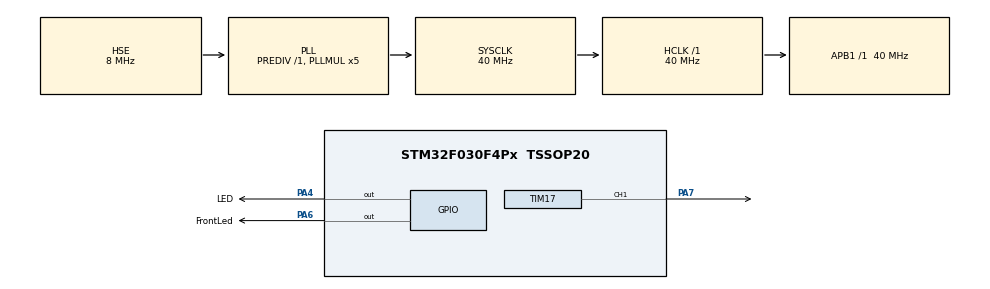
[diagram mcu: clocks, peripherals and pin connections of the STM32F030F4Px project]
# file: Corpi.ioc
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Dma.Request0=TIM17_CH1/UP
Dma.TIM17_CH1/UP.0.Direction=DMA_MEMORY_TO_PERIPH
Dma.TIM17_CH1/UP.0.Instance=DMA1_Channel1
Dma.TIM17_CH1/UP.0.MemDataAlignment=DMA_MDATAALIGN_HALFWORD
Dma.TIM17_CH1/UP.0.MemInc=DMA_MINC_ENABLE
Dma.TIM17_CH1/UP.0.Mode=DMA_NORMAL
Dma.TIM17_CH1/UP.0.PeriphDataAlignment=DMA_PDATAALIGN_HALFWORD
Dma.TIM17_CH1/UP.0.PeriphInc=DMA_PINC_DISABLE
Dma.TIM17_CH1/UP.0.Priority=DMA_PRIORITY_LOW
Mcu.Family=STM32F0
Mcu.Name=STM32F030F4Px
Mcu.Package=TSSOP20
NVIC.DMA1_Channel1_IRQn=true\:0\:0\:false\:false\:true\:false\:true
PA13.Mode=Serial_Wire
PA13.Signal=SYS_SWDIO
PA14.Mode=Serial_Wire
PA14.Signal=SYS_SWCLK
PA4.GPIO_Label=LED
PA4.Signal=GPIO_Output
PA6.GPIO_Label=FrontLed
PA6.Signal=GPIO_Output
PA7.Signal=S_TIM17_CH1
PF0-OSC_IN.Mode=HSE-External-Oscillator
PF0-OSC_IN.Signal=RCC_OSC_IN
PF1-OSC_OUT.Mode=HSE-External-Oscillator
PF1-OSC_OUT.Signal=RCC_OSC_OUT
ProjectManager.HeapSize=0x200
ProjectManager.StackSize=0x400
ProjectManager.TargetToolchain=STM32CubeIDE
RCC.AHBFreq_Value=40000000
RCC.APB1Freq_Value=40000000
RCC.APB1TimFreq_Value=40000000
RCC.HCLKFreq_Value=40000000
RCC.PLLMUL=RCC_PLL_MUL5
RCC.PLLSourceVirtual=RCC_PLLSOURCE_HSE
RCC.SYSCLKFreq_VALUE=40000000
RCC.SYSCLKSource=RCC_SYSCLKSOURCE_PLLCLK
SH.S_TIM17_CH1.0=TIM17_CH1,PWM Generation1 CH1
TIM17.Channel=TIM_CHANNEL_1
TIM17.Period=50-1
VP_TIM17_VS_ClockSourceINT.Mode=Enable_Timer
board=custom

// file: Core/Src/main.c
/* USER CODE BEGIN Header */
/**
  ******************************************************************************
  * @file           : main.c
  * @brief          : Main program body
  ******************************************************************************
  * @attention
  *
  * Copyright (c) 2022 STMicroelectronics.
  * All rights reserved.
  *
  * This software is licensed under terms that can be found in the LICENSE file
  * in the root directory of this software component.
  * If no LICENSE file comes with this software, it is provided AS-IS.
  *
  ******************************************************************************
  */
/* USER CODE END Header */
#include "main.h"

/* USER CODE BEGIN Includes */
#include "WS2812.h"
//#include "APP.h"
/* USER CODE END Includes */

TIM_HandleTypeDef htim17;
DMA_HandleTypeDef hdma_tim17_ch1_up;

void SystemClock_Config(void);
static void MX_GPIO_Init(void);
static void MX_DMA_Init(void);
static void MX_TIM17_Init(void);

/* USER CODE BEGIN 0 */
void HAL_TIM_PWM_PulseFinishedCallback(TIM_HandleTypeDef *htim) {
	if (htim->Instance == TIM17) {
		HAL_TIM_PWM_Stop_DMA(&htim17, TIM_CHANNEL_1);
		WS2812_DMACallBack();
		HAL_GPIO_TogglePin(LED_GPIO_Port, LED_Pin);
	}
}
/* USER CODE END 0 */

int main(void)
{

  /* MCU Configuration--------------------------------------------------------*/

  /* Reset of all peripherals, Initializes the Flash interface and the Systick. */
  HAL_Init();

  /* Configure the system clock */
  SystemClock_Config();

  /* Initialize all configured peripherals */
  MX_GPIO_Init();
  MX_DMA_Init();
  MX_TIM17_Init();
  /* USER CODE BEGIN 2 */

//  CORPI_init();
  WS2812_init();

  WS2812_colorStruct r = (WS2812_colorStruct) {10, 0, 0};
  WS2812_colorStruct g = (WS2812_colorStruct) {0, 10, 0};
  WS2812_colorStruct b = (WS2812_colorStruct) {0, 0, 10};

  WS2812_setOne(r, 0);
  	  WS2812_setOne(g, 1);
  	  WS2812_setOne(b, 2);
//  WS2812_refresh(htim1, TIM_CHANNEL_1);

  /* USER CODE END 2 */

  /* Infinite loop */
  /* USER CODE BEGIN WHILE */
  while (1)
  {
//	  HAL_GPIO_TogglePin(LED_GPIO_Port, LED_Pin);
	  // --------------------------------------- set 3 leds
	  // --------------------------------------- set 3 leds
	  WS2812_setOne(r, 0);
	  WS2812_setOne(g, 1);
	  WS2812_setOne(b, 2);

	  WS2812_refresh(htim17, TIM_CHANNEL_1);
	  HAL_Delay(3000);

	  // --------------------------------------- rotate next
	  WS2812_rotateNext();
	  WS2812_refresh(htim17, TIM_CHANNEL_1);
	  HAL_Delay(1000);

	  WS2812_rotateNext();
	  WS2812_refresh(htim17, TIM_CHANNEL_1);
	  HAL_Delay(1000);

	  WS2812_rotateNext();
	  WS2812_refresh(htim17, TIM_CHANNEL_1);
	  HAL_Delay(1000);

	  // --------------------------------------- rotate previous
	  WS2812_rotatePrevious();
	  WS2812_refresh(htim17, TIM_CHANNEL_1);
	  HAL_Delay(1000);

	  WS2812_rotatePrevious();
	  WS2812_refresh(htim17, TIM_CHANNEL_1);
	  HAL_Delay(1000);

	  WS2812_rotatePrevious();
	  WS2812_refresh(htim17, TIM_CHANNEL_1);
	  HAL_Delay(1000);

	  // --------------------------------------- shift next
	  WS2812_shiftNext(r);
	  WS2812_refresh(htim17, TIM_CHANNEL_1);
	  HAL_Delay(1000);

	  WS2812_shiftNext(r);
	  WS2812_refresh(htim17, TIM_CHANNEL_1);
	  HAL_Delay(1000);

	  // --------------------------------------- reset to shift previous
	  WS2812_setOne(r, 0);
	  WS2812_setOne(g, 1);
	  WS2812_setOne(b, 2);
	  WS2812_refresh(htim17, TIM_CHANNEL_1);
	  HAL_Delay(1000);

	  WS2812_shiftPrevious(r);
	  WS2812_refresh(htim17, TIM_CHANNEL_1);
	  HAL_Delay(1000);

	  WS2812_shiftPrevious(r);
	  WS2812_refresh(htim17, TIM_CHANNEL_1);
	  HAL_Delay(1000);

//	  HAL_GPIO_WritePin(LED_GPIO_Port, LED_Pin, 1);
//	  HAL_Delay(500);
//	  HAL_GPIO_WritePin(LED_GPIO_Port, LED_Pin, 0);
//	  HAL_Delay(500);

    /* USER CODE END WHILE */

  }
}

void SystemClock_Config(void)
{
  RCC_OscInitTypeDef RCC_OscInitStruct = {0};
  RCC_ClkInitTypeDef RCC_ClkInitStruct = {0};

  /** Initializes the RCC Oscillators according to the specified parameters
  * in the RCC_OscInitTypeDef structure.
  */
  RCC_OscInitStruct.OscillatorType = RCC_OSCILLATORTYPE_HSE;
  RCC_OscInitStruct.HSEState = RCC_HSE_ON;
  RCC_OscInitStruct.PLL.PLLState = RCC_PLL_ON;
  RCC_OscInitStruct.PLL.PLLSource = RCC_PLLSOURCE_HSE;
  RCC_OscInitStruct.PLL.PLLMUL = RCC_PLL_MUL5;
  RCC_OscInitStruct.PLL.PREDIV = RCC_PREDIV_DIV1;
  if (HAL_RCC_OscConfig(&RCC_OscInitStruct) != HAL_OK)
  {
    Error_Handler();
  }
  /** Initializes the CPU, AHB and APB buses clocks
  */
  RCC_ClkInitStruct.ClockType = RCC_CLOCKTYPE_HCLK|RCC_CLOCKTYPE_SYSCLK
                              |RCC_CLOCKTYPE_PCLK1;
  RCC_ClkInitStruct.SYSCLKSource = RCC_SYSCLKSOURCE_PLLCLK;
  RCC_ClkInitStruct.AHBCLKDivider = RCC_SYSCLK_DIV1;
  RCC_ClkInitStruct.APB1CLKDivider = RCC_HCLK_DIV1;

  if (HAL_RCC_ClockConfig(&RCC_ClkInitStruct, FLASH_LATENCY_1) != HAL_OK)
  {
    Error_Handler();
  }
}

static void MX_TIM17_Init(void)
{

  TIM_OC_InitTypeDef sConfigOC = {0};
  TIM_BreakDeadTimeConfigTypeDef sBreakDeadTimeConfig = {0};

  htim17.Instance = TIM17;
  htim17.Init.Prescaler = 0;
  htim17.Init.CounterMode = TIM_COUNTERMODE_UP;
  htim17.Init.Period = 50-1;
  htim17.Init.ClockDivision = TIM_CLOCKDIVISION_DIV1;
  htim17.Init.RepetitionCounter = 0;
  htim17.Init.AutoReloadPreload = TIM_AUTORELOAD_PRELOAD_DISABLE;
  if (HAL_TIM_Base_Init(&htim17) != HAL_OK)
  {
    Error_Handler();
  }
  if (HAL_TIM_PWM_Init(&htim17) != HAL_OK)
  {
    Error_Handler();
  }
  sConfigOC.OCMode = TIM_OCMODE_PWM1;
  sConfigOC.Pulse = 0;
  sConfigOC.OCPolarity = TIM_OCPOLARITY_HIGH;
  sConfigOC.OCNPolarity = TIM_OCNPOLARITY_HIGH;
  sConfigOC.OCFastMode = TIM_OCFAST_DISABLE;
  sConfigOC.OCIdleState = TIM_OCIDLESTATE_RESET;
  sConfigOC.OCNIdleState = TIM_OCNIDLESTATE_RESET;
  if (HAL_TIM_PWM_ConfigChannel(&htim17, &sConfigOC, TIM_CHANNEL_1) != HAL_OK)
  {
    Error_Handler();
  }
  sBreakDeadTimeConfig.OffStateRunMode = TIM_OSSR_DISABLE;
  sBreakDeadTimeConfig.OffStateIDLEMode = TIM_OSSI_DISABLE;
  sBreakDeadTimeConfig.LockLevel = TIM_LOCKLEVEL_OFF;
  sBreakDeadTimeConfig.DeadTime = 0;
  sBreakDeadTimeConfig.BreakState = TIM_BREAK_DISABLE;
  sBreakDeadTimeConfig.BreakPolarity = TIM_BREAKPOLARITY_HIGH;
  sBreakDeadTimeConfig.AutomaticOutput = TIM_AUTOMATICOUTPUT_DISABLE;
  if (HAL_TIMEx_ConfigBreakDeadTime(&htim17, &sBreakDeadTimeConfig) != HAL_OK)
  {
    Error_Handler();
  }
  HAL_TIM_MspPostInit(&htim17);

}

static void MX_DMA_Init(void)
{

  /* DMA controller clock enable */
  __HAL_RCC_DMA1_CLK_ENABLE();

  /* DMA interrupt init */
  /* DMA1_Channel1_IRQn interrupt configuration */
  HAL_NVIC_SetPriority(DMA1_Channel1_IRQn, 0, 0);
  HAL_NVIC_EnableIRQ(DMA1_Channel1_IRQn);

}

static void MX_GPIO_Init(void)
{
  GPIO_InitTypeDef GPIO_InitStruct = {0};

  /* GPIO Ports Clock Enable */
  __HAL_RCC_GPIOF_CLK_ENABLE();
  __HAL_RCC_GPIOA_CLK_ENABLE();

  /*Configure GPIO pin Output Level */
  HAL_GPIO_WritePin(GPIOA, LED_Pin|FrontLed_Pin, GPIO_PIN_RESET);

  /*Configure GPIO pins : LED_Pin FrontLed_Pin */
  GPIO_InitStruct.Pin = LED_Pin|FrontLed_Pin;
  GPIO_InitStruct.Mode = GPIO_MODE_OUTPUT_PP;
  GPIO_InitStruct.Pull = GPIO_NOPULL;
  GPIO_InitStruct.Speed = GPIO_SPEED_FREQ_LOW;
  HAL_GPIO_Init(GPIOA, &GPIO_InitStruct);

}

void Error_Handler(void)
{
  __disable_irq();
  while (1)
  {
  }
}
